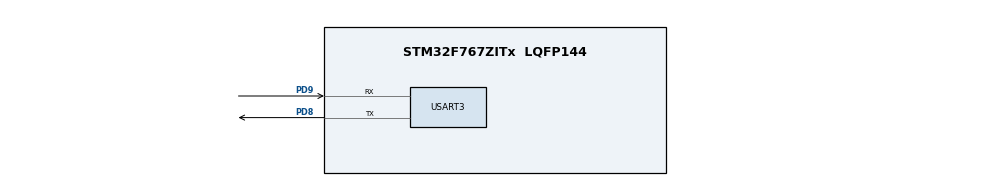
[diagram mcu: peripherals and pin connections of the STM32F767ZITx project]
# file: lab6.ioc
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CORTEX_M7.default_mode_Activation=1
Mcu.Family=STM32F7
Mcu.Name=STM32F767ZITx
Mcu.Package=LQFP144
NVIC.PriorityGroup=NVIC_PRIORITYGROUP_2
NVIC.TIM1_UP_TIM10_IRQn=true\:1\:0\:true\:false\:true\:true\:true\:true
NVIC.TIM2_IRQn=true\:2\:0\:true\:false\:true\:true\:true\:true
NVIC.USART3_IRQn=true\:0\:0\:false\:false\:true\:true\:true\:true
PD8.Mode=Asynchronous
PD8.Signal=USART3_TX
PD9.Mode=Asynchronous
PD9.Signal=USART3_RX
ProjectManager.HeapSize=0x200
ProjectManager.StackSize=0x400
ProjectManager.TargetToolchain=STM32CubeIDE
RCC.HSE_VALUE=25000000
RCC.HSI_VALUE=16000000
RCC.LSE_VALUE=32768
RCC.USBFreq_Value=96000000
RCC.VCOOutputFreq_Value=192000000
TIM1.Period=1000-1
TIM1.Prescaler=216-1
TIM2.Period=0
USART3.VirtualMode-Asynchronous=VM_ASYNC
VP_TIM1_VS_ClockSourceINT.Mode=Internal
VP_TIM2_VS_ClockSourceINT.Mode=Internal
board=custom

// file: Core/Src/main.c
/* USER CODE BEGIN Header */
/**
  ******************************************************************************
  * @file           : main.c
  * @brief          : Main program body
  ******************************************************************************
  * @attention
  *
  * Copyright (c) 2025 STMicroelectronics.
  * All rights reserved.
  *
  * This software is licensed under terms that can be found in the LICENSE file
  * in the root directory of this software component.
  * If no LICENSE file comes with this software, it is provided AS-IS.
  *
  ******************************************************************************
  */
/* USER CODE END Header */
#include "main.h"

/* USER CODE BEGIN PD */

uint32_t count;

/* USER CODE END PD */

TIM_HandleTypeDef htim1;
TIM_HandleTypeDef htim2;

UART_HandleTypeDef huart3;

void SystemClock_Config(void);
static void MPU_Config(void);
static void MX_GPIO_Init(void);
static void MX_TIM1_Init(void);
static void MX_TIM2_Init(void);
static void MX_USART3_UART_Init(void);

/* USER CODE BEGIN 0 */
void displayNumber()
{
	HAL_UART_Transmit(&huart3, (uint8_t*)count, sizeof(count), HAL_MAX_DELAY);
}
/* USER CODE END 0 */

int main(void)
{

  /* MPU Configuration--------------------------------------------------------*/
  MPU_Config();

  /* MCU Configuration--------------------------------------------------------*/

  /* Reset of all peripherals, Initializes the Flash interface and the Systick. */
  HAL_Init();

  /* Configure the system clock */
  SystemClock_Config();

  /* Initialize all configured peripherals */
  MX_GPIO_Init();
  MX_TIM1_Init();
  MX_TIM2_Init();
  MX_USART3_UART_Init();
  /* USER CODE BEGIN 2 */

  HAL_TIM_Base_Start_IT(&htim1);

  /* USER CODE END 2 */

  /* Infinite loop */
  while (1)
  {

    /* USER CODE BEGIN 3 */

	  displayNumber;
  }
  /* USER CODE END 3 */
}

void SystemClock_Config(void)
{
  RCC_OscInitTypeDef RCC_OscInitStruct = {0};
  RCC_ClkInitTypeDef RCC_ClkInitStruct = {0};

  /** Configure the main internal regulator output voltage
  */
  __HAL_RCC_PWR_CLK_ENABLE();
  __HAL_PWR_VOLTAGESCALING_CONFIG(PWR_REGULATOR_VOLTAGE_SCALE3);

  /** Initializes the RCC Oscillators according to the specified parameters
  * in the RCC_OscInitTypeDef structure.
  */
  RCC_OscInitStruct.OscillatorType = RCC_OSCILLATORTYPE_HSI;
  RCC_OscInitStruct.HSIState = RCC_HSI_ON;
  RCC_OscInitStruct.HSICalibrationValue = RCC_HSICALIBRATION_DEFAULT;
  RCC_OscInitStruct.PLL.PLLState = RCC_PLL_NONE;
  if (HAL_RCC_OscConfig(&RCC_OscInitStruct) != HAL_OK)
  {
    Error_Handler();
  }

  /** Initializes the CPU, AHB and APB buses clocks
  */
  RCC_ClkInitStruct.ClockType = RCC_CLOCKTYPE_HCLK|RCC_CLOCKTYPE_SYSCLK
                              |RCC_CLOCKTYPE_PCLK1|RCC_CLOCKTYPE_PCLK2;
  RCC_ClkInitStruct.SYSCLKSource = RCC_SYSCLKSOURCE_HSI;
  RCC_ClkInitStruct.AHBCLKDivider = RCC_SYSCLK_DIV1;
  RCC_ClkInitStruct.APB1CLKDivider = RCC_HCLK_DIV1;
  RCC_ClkInitStruct.APB2CLKDivider = RCC_HCLK_DIV1;

  if (HAL_RCC_ClockConfig(&RCC_ClkInitStruct, FLASH_LATENCY_0) != HAL_OK)
  {
    Error_Handler();
  }
}

static void MX_TIM1_Init(void)
{

  TIM_ClockConfigTypeDef sClockSourceConfig = {0};
  TIM_MasterConfigTypeDef sMasterConfig = {0};

  htim1.Instance = TIM1;
  htim1.Init.Prescaler = 216-1;
  htim1.Init.CounterMode = TIM_COUNTERMODE_UP;
  htim1.Init.Period = 1000-1;
  htim1.Init.ClockDivision = TIM_CLOCKDIVISION_DIV1;
  htim1.Init.RepetitionCounter = 0;
  htim1.Init.AutoReloadPreload = TIM_AUTORELOAD_PRELOAD_DISABLE;
  if (HAL_TIM_Base_Init(&htim1) != HAL_OK)
  {
    Error_Handler();
  }
  sClockSourceConfig.ClockSource = TIM_CLOCKSOURCE_INTERNAL;
  if (HAL_TIM_ConfigClockSource(&htim1, &sClockSourceConfig) != HAL_OK)
  {
    Error_Handler();
  }
  sMasterConfig.MasterOutputTrigger = TIM_TRGO_RESET;
  sMasterConfig.MasterOutputTrigger2 = TIM_TRGO2_RESET;
  sMasterConfig.MasterSlaveMode = TIM_MASTERSLAVEMODE_DISABLE;
  if (HAL_TIMEx_MasterConfigSynchronization(&htim1, &sMasterConfig) != HAL_OK)
  {
    Error_Handler();
  }

}

static void MX_TIM2_Init(void)
{

  TIM_ClockConfigTypeDef sClockSourceConfig = {0};
  TIM_MasterConfigTypeDef sMasterConfig = {0};

  htim2.Instance = TIM2;
  htim2.Init.Prescaler = 0;
  htim2.Init.CounterMode = TIM_COUNTERMODE_UP;
  htim2.Init.Period = 0;
  htim2.Init.ClockDivision = TIM_CLOCKDIVISION_DIV1;
  htim2.Init.AutoReloadPreload = TIM_AUTORELOAD_PRELOAD_DISABLE;
  if (HAL_TIM_Base_Init(&htim2) != HAL_OK)
  {
    Error_Handler();
  }
  sClockSourceConfig.ClockSource = TIM_CLOCKSOURCE_INTERNAL;
  if (HAL_TIM_ConfigClockSource(&htim2, &sClockSourceConfig) != HAL_OK)
  {
    Error_Handler();
  }
  sMasterConfig.MasterOutputTrigger = TIM_TRGO_RESET;
  sMasterConfig.MasterSlaveMode = TIM_MASTERSLAVEMODE_DISABLE;
  if (HAL_TIMEx_MasterConfigSynchronization(&htim2, &sMasterConfig) != HAL_OK)
  {
    Error_Handler();
  }

}

static void MX_USART3_UART_Init(void)
{

  huart3.Instance = USART3;
  huart3.Init.BaudRate = 115200;
  huart3.Init.WordLength = UART_WORDLENGTH_8B;
  huart3.Init.StopBits = UART_STOPBITS_1;
  huart3.Init.Parity = UART_PARITY_NONE;
  huart3.Init.Mode = UART_MODE_TX_RX;
  huart3.Init.HwFlowCtl = UART_HWCONTROL_NONE;
  huart3.Init.OverSampling = UART_OVERSAMPLING_16;
  huart3.Init.OneBitSampling = UART_ONE_BIT_SAMPLE_DISABLE;
  huart3.AdvancedInit.AdvFeatureInit = UART_ADVFEATURE_NO_INIT;
  if (HAL_UART_Init(&huart3) != HAL_OK)
  {
    Error_Handler();
  }

}

static void MX_GPIO_Init(void)
{

  /* GPIO Ports Clock Enable */
  __HAL_RCC_GPIOD_CLK_ENABLE();

}

 /* MPU Configuration */

void MPU_Config(void)
{
  MPU_Region_InitTypeDef MPU_InitStruct = {0};

  /* Disables the MPU */
  HAL_MPU_Disable();

  /** Initializes and configures the Region and the memory to be protected
  */
  MPU_InitStruct.Enable = MPU_REGION_ENABLE;
  MPU_InitStruct.Number = MPU_REGION_NUMBER0;
  MPU_InitStruct.BaseAddress = 0x0;
  MPU_InitStruct.Size = MPU_REGION_SIZE_4GB;
  MPU_InitStruct.SubRegionDisable = 0x87;
  MPU_InitStruct.TypeExtField = MPU_TEX_LEVEL0;
  MPU_InitStruct.AccessPermission = MPU_REGION_NO_ACCESS;
  MPU_InitStruct.DisableExec = MPU_INSTRUCTION_ACCESS_DISABLE;
  MPU_InitStruct.IsShareable = MPU_ACCESS_SHAREABLE;
  MPU_InitStruct.IsCacheable = MPU_ACCESS_NOT_CACHEABLE;
  MPU_InitStruct.IsBufferable = MPU_ACCESS_NOT_BUFFERABLE;

  HAL_MPU_ConfigRegion(&MPU_InitStruct);
  /* Enables the MPU */
  HAL_MPU_Enable(MPU_PRIVILEGED_DEFAULT);

}

void Error_Handler(void)
{
  __disable_irq();
  while (1)
  {
  }
}
